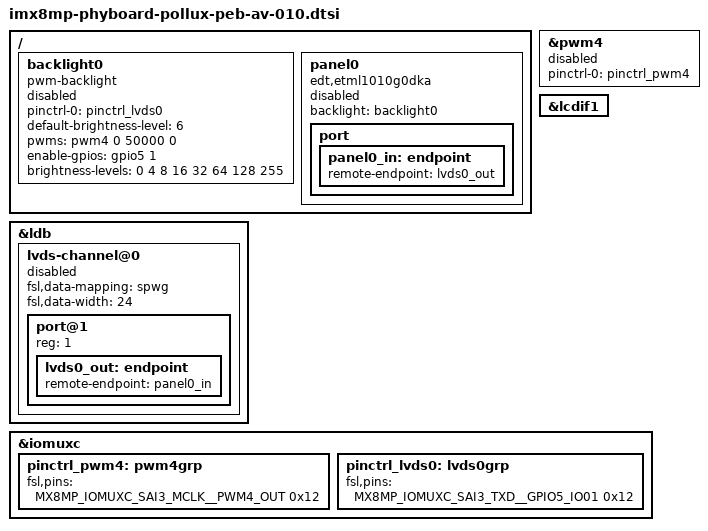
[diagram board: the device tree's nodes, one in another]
// SPDX-License-Identifier: GPL-2.0
/*
 * Copyright (C) 2020 PHYTEC Messtechnik GmbH
 * Author: Teresa Remmet <t.remmet@phytec.de>
 *
 */

/ {
	backlight0: backlight0 {
		compatible = "pwm-backlight";
		pinctrl-names = "default";
		pinctrl-0 = <&pinctrl_lvds0>;
		default-brightness-level = <6>;
		pwms = <&pwm4 0 50000 0>;
		enable-gpios = <&gpio5 1 GPIO_ACTIVE_HIGH>;
		brightness-levels= <0 4 8 16 32 64 128 255>;
		status = "disabled";
	};

	panel0: panel0 {
		compatible = "edt,etml1010g0dka";
		backlight = <&backlight0>;
		status = "disabled";

		port {
			panel0_in: endpoint {
				remote-endpoint = <&lvds0_out>;
			};
		};
	};
};

&pwm4 {
	status = "disabled";
	pinctrl-names = "default";
	pinctrl-0 = <&pinctrl_pwm4>;
};

&lcdif1 {
	status = "okay";
};

&ldb {
	lvds-channel@0 {
		fsl,data-mapping = "spwg";
		fsl,data-width = <24>;
		status = "disabled";

		port@1 {
			reg = <1>;

			lvds0_out: endpoint {
				remote-endpoint = <&panel0_in>;
			};
		};
	};
};

&iomuxc {
	pinctrl-names = "default";

	pinctrl_pwm4: pwm4grp {
		fsl,pins = <
			MX8MP_IOMUXC_SAI3_MCLK__PWM4_OUT		0x12
		>;
	};

	pinctrl_lvds0: lvds0grp {
		fsl,pins = <
			MX8MP_IOMUXC_SAI3_TXD__GPIO5_IO01		0x12
		>;
	};
};
